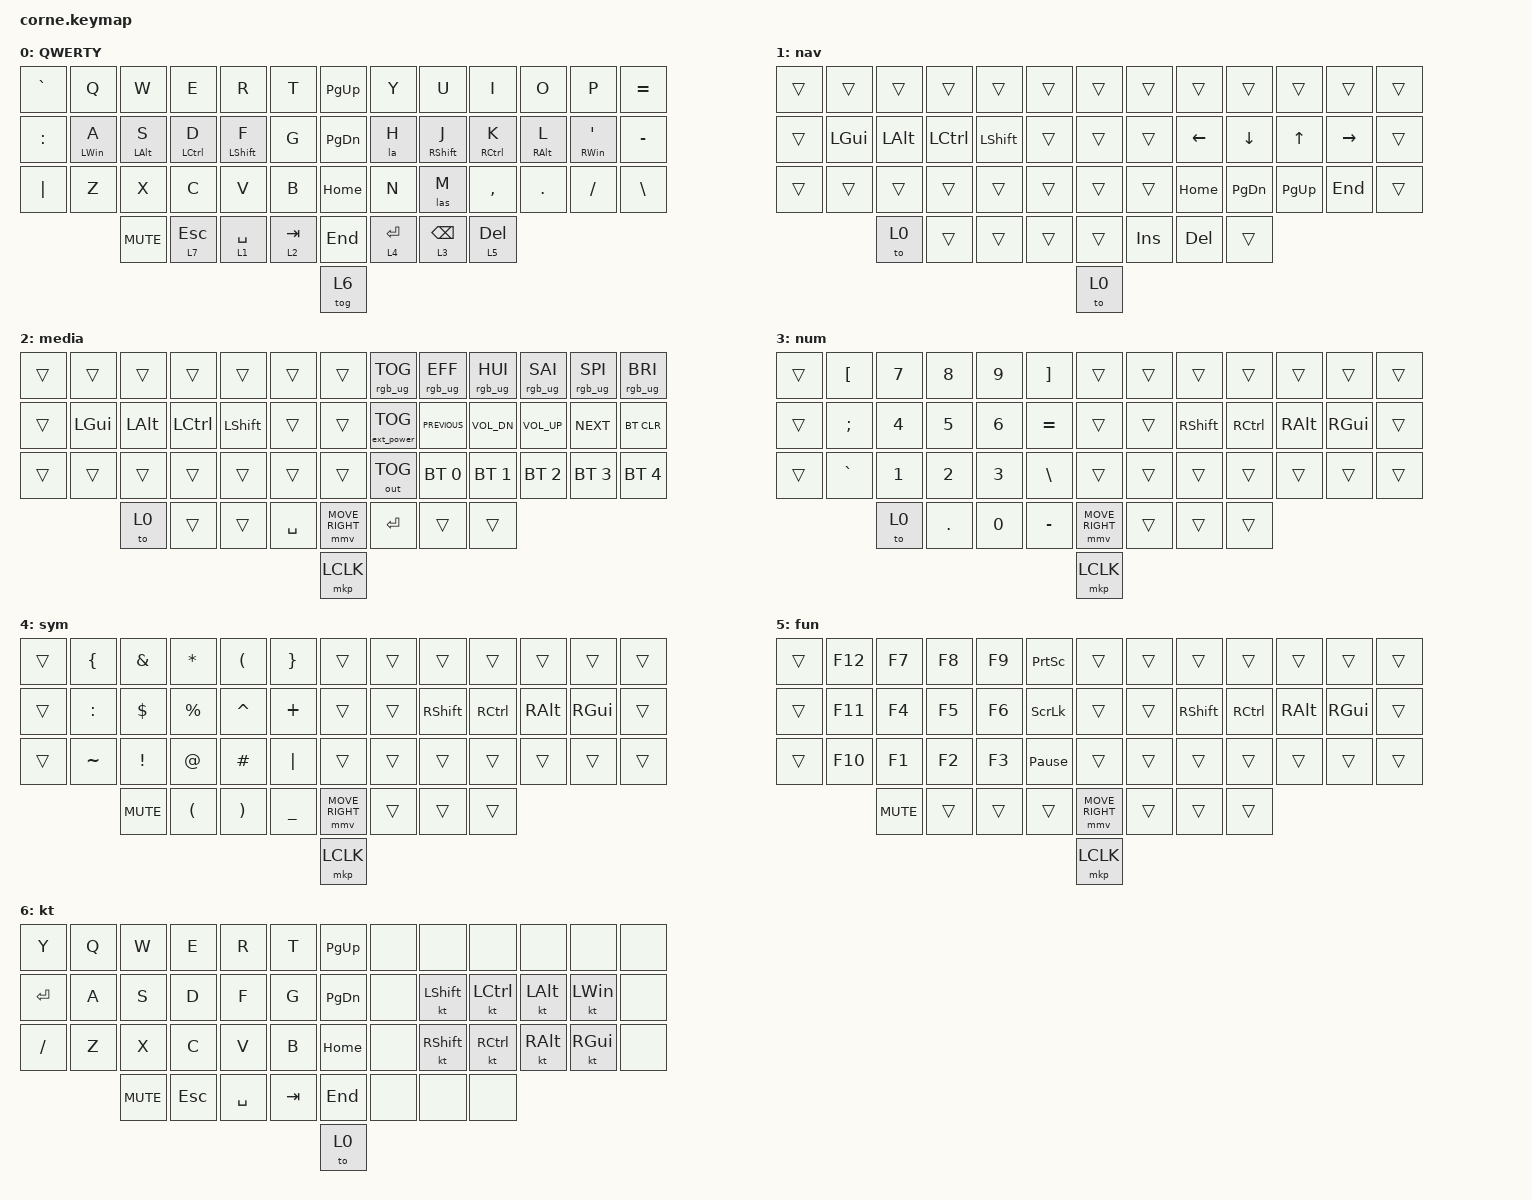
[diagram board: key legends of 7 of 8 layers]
#include <behaviors/mouse_keys.dtsi>
#include <behaviors.dtsi>
#include <dt-bindings/zmk/bt.h>
#include <dt-bindings/zmk/ext_power.h>
#include <dt-bindings/zmk/keys.h>
#include <dt-bindings/zmk/keys.h>
#include <dt-bindings/zmk/mouse.h>
#include <dt-bindings/zmk/outputs.h>
#include <dt-bindings/zmk/rgb.h>

#define ZMK_MOUSE_DEFAULT_MOVE_VAL 1200  // 600
#define ZMK_MOUSE_DEFAULT_SCRL_VAL 20    // 10
#define U_MS_U &mmv MOVE_UP
#define U_MS_D &mmv MOVE_DOWN
#define U_MS_L &mmv MOVE_LEFT
#define U_MS_R &mmv MOVE_RIGHT

&lt {
    quick-tap-ms = <200>;
    flavor = "hold-preferred";
};

&mt {
    quick-tap-ms = <200>;
    flavor = "tap-preferred";
};

/ {
    behaviors {
        td0: td0 {
            compatible = "zmk,behavior-tap-dance";
            label = "TD0";
            #binding-cells = <0>;
            bindings = <&kp LEFT_SHIFT>, <&kp CAPS>;
        };

        mmv {
            acceleration-exponent = <1>;      // 1
            time-to-max-speed-ms = <900>;    // 40
            delay-ms = <0>;                   // 0
        };

        msc {
            acceleration-exponent = <1>;      // 0
            time-to-max-speed-ms = <400>;      // 500
            delay-ms = <0>;                   // 10
        };
    };

    rgb_encoder: rgb_encoder {
        compatible = "zmk,behavior-sensor-rotate";
        label = "RGB_ENCODER";
        #sensor-binding-cells = <0>;
        bindings = <&rgb_ug RGB_BRI>, <&rgb_ug RGB_BRD>;
    };

    scroll_encoder: scroll_encoder {
        compatible = "zmk,behavior-sensor-rotate";
        #sensor-binding-cells = <0>;
        bindings = <&msc SCRL_DOWN>, <&msc SCRL_UP>;

        tap-ms = <30>;
    };

    la: la {
        compatible = "zmk,behavior-macro";
        wait-ms = <0>;
        tap-ms = <0>;
        #binding-cells = <0>;
        bindings =
            <&macro_press>,
            <&mo 3 &kp LALT>,
            <&macro_pause_for_release>,
            <&macro_release>,
            <&mo 3 &kp LALT>;
    };

    las: las {
        compatible = "zmk,behavior-macro";
        wait-ms = <0>;
        tap-ms = <0>;
        #binding-cells = <0>;
        bindings =
            <&macro_press>,
            <&mo 3 &kp LALT &kp LSHIFT>,
            <&macro_pause_for_release>,
            <&macro_release>,
            <&mo 3 &kp LALT &kp LSHIFT>;
    };

    al: al {
        compatible = "zmk,behavior-hold-tap";
        #binding-cells = <2>;
        flavor = "tap-preferred";
        tapping-term-ms = <300>;
        quick-tap-ms = <125>;
        global-quick-tap;
        bindings = <&la>, <&kp>;

        require-prior-idle-ms = <125>;
    };

    asl: asl {
        compatible = "zmk,behavior-hold-tap";
        #binding-cells = <2>;
        flavor = "tap-preferred";
        tapping-term-ms = <300>;
        quick-tap-ms = <125>;
        global-quick-tap;
        bindings = <&las>, <&kp>;

        require-prior-idle-ms = <125>;
    };

    macros {
    };

    keymap {
        compatible = "zmk,keymap";

        base {
            display-name = "QWERTY";

            // --------------------------------------------------------------------------------
            // |  TAB |  Q  |  W  |  E  |  R  |  T  |                ↑    |  Y  |  U   |  I  |  O  |  P  | BKSP |      &kp UP_ARROW 
            // | SHIFT |  A  |  S  |  D  |  F  |  G  |               ↓    |  H  |  J   |  K  |  L  |  ;  |  '   | 
            // | CTRL |  Z  |  X  |  C  |  V  |  B  |                ←    |  N  |  M   |  ,  |  .  |  /  | ESC  |
            //                    | GUI | LWR | SPC |                →    | ENT | RSE  | ALT |
            //                                                      enter

            bindings = <
&kp GRAVE  &kp Q       &kp W       &kp E        &kp R        &kp T        &kp PG_UP  &kp Y        &kp U            &kp I        &kp O       &kp P              &kp EQUAL
&kp COLON  &mt LWIN A  &mt LALT S  &mt LCTRL D  &mt LSHFT F  &kp G        &kp PG_DN  &al 0 H      &mt RSHFT J      &mt RCTRL K  &mt RALT L  &mt RIGHT_WIN SQT  &kp MINUS
&kp PIPE   &kp Z       &kp X       &kp C        &kp V        &kp B        &kp HOME   &kp N        &asl 0 M         &kp COMMA    &kp DOT     &kp FSLH           &kp BACKSLASH
                       &kp C_MUTE  &lt 7 ESC    &lt 1 SPACE  &lt 2 TAB    &kp END    &lt 4 ENTER  &lt 3 BACKSPACE  &lt 5 DEL
                                                                          &tog 6
            >;

            label = "QWERTY";
            sensor-bindings = <&inc_dec_kp RIGHT LEFT>;
        };

        nav {
            display-name = "nav";

            // -----------------------------------------------------------------------------------------
            // |  TAB |  1  |  2  |  3  |  4  |  5  |   |  6  |  7  |  8  |  9  |  0  | BKSP |
            // | BTCLR| BT1 | BT2 | BT3 | BT4 | BT5 |   | LFT | DWN |  UP | RGT |     |      |
            // | SHFT |     |     |     |     |     |   |     |     |     |     |     |      |
            //                    | GUI |     | SPC |   | ENT |     | ALT |

            bindings = <
&trans  &trans    &trans    &trans     &trans     &trans    &trans  &trans   &trans    &trans     &trans     &trans     &trans
&trans  &kp LGUI  &kp LALT  &kp LCTRL  &kp LSHFT  &trans    &trans  &trans   &kp LEFT  &kp DOWN   &kp UP     &kp RIGHT  &trans
&trans  &trans    &trans    &trans     &trans     &trans    &trans  &trans   &kp HOME  &kp PG_DN  &kp PG_UP  &kp END    &trans
                  &to 0     &trans     &trans     &trans    &trans  &kp INS  &kp DEL   &trans
                                                            &to 0
            >;

            label = "nav";
            sensor-bindings = <&scroll_encoder>;
        };

        media {
            display-name = "media";

            // -----------------------------------------------------------------------------------------
            // |  TAB |  !  |  @  |  #  |  $  |  %  |   |  ^  |  &  |  *  |  (  |  )  | BKSP |
            // | CTRL |     |     |     |     |     |   |  -  |  =  |  [  |  ]  |  \  |  `   |
            // | SHFT |     |     |     |     |     |   |  _  |  +  |  {  |  }  | "|" |  ~   |
            //                    | GUI |     | SPC |   | ENT |     | ALT |

            bindings = <
&trans  &trans    &trans    &trans     &trans     &trans       &trans           &rgb_ug RGB_TOG    &rgb_ug RGB_EFF  &rgb_ug RGB_HUI  &rgb_ug RGB_SAI  &rgb_ug RGB_SPI  &rgb_ug RGB_BRI
&trans  &kp LGUI  &kp LALT  &kp LCTRL  &kp LSHFT  &trans       &trans           &ext_power EP_TOG  &kp C_PREVIOUS   &kp C_VOL_DN     &kp C_VOL_UP     &kp C_NEXT       &bt BT_CLR
&trans  &trans    &trans    &trans     &trans     &trans       &trans           &out OUT_TOG       &bt BT_SEL 0     &bt BT_SEL 1     &bt BT_SEL 2     &bt BT_SEL 3     &bt BT_SEL 4
                  &to 0     &trans     &trans     &kp SPACE    &mmv MOVE_RIGHT  &kp RET            &trans           &trans
                                                               &mkp LCLK
            >;

            label = "media";
            sensor-bindings = <&scroll_encoder>;
        };

        num {
            display-name = "num";
            bindings = <
&trans  &kp LBKT   &kp N7  &kp N8   &kp N9  &kp RBKT     &trans           &trans  &trans     &trans     &trans    &trans    &trans
&trans  &kp SEMI   &kp N4  &kp N5   &kp N6  &kp EQUAL    &trans           &trans  &kp RSHFT  &kp RCTRL  &kp RALT  &kp RGUI  &trans
&trans  &kp GRAVE  &kp N1  &kp N2   &kp N3  &kp BSLH     &trans           &trans  &trans     &trans     &trans    &trans    &trans
                   &to 0   &kp DOT  &kp N0  &kp MINUS    &mmv MOVE_RIGHT  &trans  &trans     &trans
                                                         &mkp LCLK
            >;

            label = "num";
            sensor-bindings = <&inc_dec_kp DOWN UP_ARROW>;
        };

        sym {
            display-name = "sym";
            bindings = <
&trans  &kp LEFT_BRACE  &kp AMPERSAND    &kp ASTERISK  &kp LEFT_PARENTHESIS  &kp RIGHT_BRACE    &trans           &trans  &trans     &trans     &trans    &trans    &trans
&trans  &kp COLON       &kp DOLLAR       &kp PERCENT   &kp CARET             &kp PLUS           &trans           &trans  &kp RSHFT  &kp RCTRL  &kp RALT  &kp RGUI  &trans
&trans  &kp TILDE       &kp EXCLAMATION  &kp AT_SIGN   &kp HASH              &kp PIPE           &trans           &trans  &trans     &trans     &trans    &trans    &trans
                        &kp C_MUTE       &kp LPAR      &kp RPAR              &kp UNDERSCORE     &mmv MOVE_RIGHT  &trans  &trans     &trans
                                                                                                &mkp LCLK
            >;

            label = "sym";
            sensor-bindings = <&scroll_encoder>;
        };

        fun {
            display-name = "fun";
            bindings = <
&trans  &kp F12  &kp F7      &kp F8  &kp F9  &kp PSCRN          &trans           &trans  &trans     &trans     &trans    &trans    &trans
&trans  &kp F11  &kp F4      &kp F5  &kp F6  &kp SCROLLLOCK     &trans           &trans  &kp RSHFT  &kp RCTRL  &kp RALT  &kp RGUI  &trans
&trans  &kp F10  &kp F1      &kp F2  &kp F3  &kp PAUSE_BREAK    &trans           &trans  &trans     &trans     &trans    &trans    &trans
                 &kp C_MUTE  &trans  &trans  &trans             &mmv MOVE_RIGHT  &trans  &trans     &trans
                                                                &mkp LCLK
            >;

            label = "fun";
            sensor-bindings = <&rgb_encoder>;
        };

        kt {
            display-name = "kt";
            bindings = <
&kp Y      &kp Q  &kp W       &kp E    &kp R      &kp T      &kp PG_UP  &none  &none      &none      &none     &none     &none
&kp ENTER  &kp A  &kp S       &kp D    &kp F      &kp G      &kp PG_DN  &none  &kt LSHFT  &kt LCTRL  &kt LALT  &kt LWIN  &none
&kp FSLH   &kp Z  &kp X       &kp C    &kp V      &kp B      &kp HOME   &none  &kt RSHFT  &kt RCTRL  &kt RALT  &kt RGUI  &none
                  &kp C_MUTE  &kp ESC  &kp SPACE  &kp TAB    &kp END    &none  &none      &none
                                                             &to 0
            >;

            label = "game";
            sensor-bindings = <&inc_dec_kp LEFT RIGHT_ARROW>;
        };

        feat {
            display-name = "feat";
            bindings = <
&trans  &bootloader  &trans    &sys_reset  &soft_off  &rgb_ug RGB_TOG      &trans  &rgb_ug RGB_TOG    &soft_off  &sys_reset  &trans  &bootloader  &trans
&trans  &kt LWIN     &kt LALT  &kt LCTRL   &kt LSHFT  &ext_power EP_TOG    &trans  &ext_power EP_TOG  &trans     &trans      &trans  &trans       &trans
&trans  &trans       &trans    &to 2       &to 1      &out OUT_TOG         &trans  &out OUT_TOG       &to 3      &to 4       &to 5   &trans       &kp C_MUTE
                     &trans    &trans      &trans     &mmv MOVE_RIGHT      &trans  &trans             &trans     &mkp LCLK
            >;

            label = "feat";
            sensor-bindings = <&scroll_encoder>;
        };
    };
};
